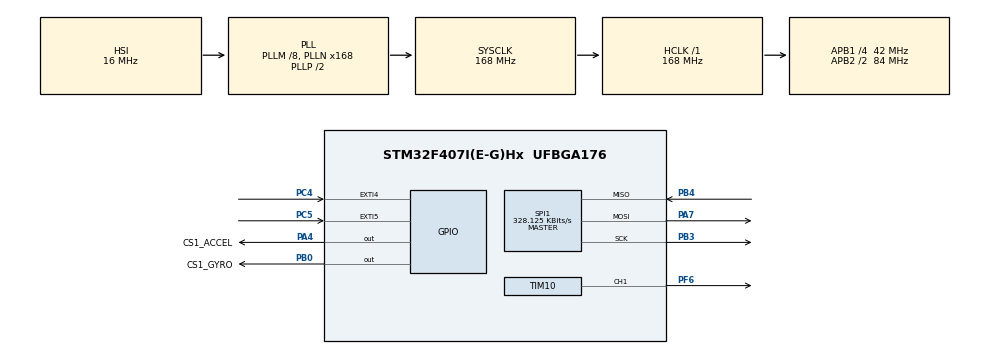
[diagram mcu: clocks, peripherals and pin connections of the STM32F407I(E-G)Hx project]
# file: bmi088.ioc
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Dma.Request0=SPI1_RX
Dma.Request1=SPI1_TX
Dma.SPI1_RX.0.Direction=DMA_PERIPH_TO_MEMORY
Dma.SPI1_RX.0.FIFOMode=DMA_FIFOMODE_DISABLE
Dma.SPI1_RX.0.Instance=DMA2_Stream2
Dma.SPI1_RX.0.MemDataAlignment=DMA_MDATAALIGN_BYTE
Dma.SPI1_RX.0.MemInc=DMA_MINC_ENABLE
Dma.SPI1_RX.0.Mode=DMA_NORMAL
Dma.SPI1_RX.0.PeriphDataAlignment=DMA_PDATAALIGN_BYTE
Dma.SPI1_RX.0.PeriphInc=DMA_PINC_DISABLE
Dma.SPI1_RX.0.Priority=DMA_PRIORITY_VERY_HIGH
Dma.SPI1_TX.1.Direction=DMA_MEMORY_TO_PERIPH
Dma.SPI1_TX.1.FIFOMode=DMA_FIFOMODE_DISABLE
Dma.SPI1_TX.1.Instance=DMA2_Stream3
Dma.SPI1_TX.1.MemDataAlignment=DMA_MDATAALIGN_BYTE
Dma.SPI1_TX.1.MemInc=DMA_MINC_ENABLE
Dma.SPI1_TX.1.Mode=DMA_NORMAL
Dma.SPI1_TX.1.PeriphDataAlignment=DMA_PDATAALIGN_BYTE
Dma.SPI1_TX.1.PeriphInc=DMA_PINC_DISABLE
Dma.SPI1_TX.1.Priority=DMA_PRIORITY_HIGH
Mcu.Family=STM32F4
Mcu.Name=STM32F407I(E-G)Hx
Mcu.Package=UFBGA176
NVIC.DMA2_Stream2_IRQn=true\:0\:0\:false\:false\:true\:false\:true\:true
NVIC.DMA2_Stream3_IRQn=true\:0\:0\:false\:false\:true\:false\:true\:true
NVIC.EXTI4_IRQn=true\:0\:0\:false\:false\:true\:true\:true\:true
NVIC.EXTI9_5_IRQn=true\:0\:0\:false\:false\:true\:true\:true\:true
NVIC.PriorityGroup=NVIC_PRIORITYGROUP_4
NVIC.TIM1_UP_TIM10_IRQn=true\:0\:0\:false\:false\:true\:true\:true\:true
PA13.Mode=Serial_Wire
PA13.Signal=SYS_JTMS-SWDIO
PA14.Mode=Serial_Wire
PA14.Signal=SYS_JTCK-SWCLK
PA4.GPIO_Label=CS1_ACCEL
PA4.GPIO_PuPd=GPIO_PULLUP
PA4.GPIO_Speed=GPIO_SPEED_FREQ_HIGH
PA4.PinState=GPIO_PIN_SET
PA4.Signal=GPIO_Output
PA7.Mode=Full_Duplex_Master
PA7.Signal=SPI1_MOSI
PB0.GPIO_Label=CS1_GYRO
PB0.GPIO_PuPd=GPIO_PULLUP
PB0.GPIO_Speed=GPIO_SPEED_FREQ_HIGH
PB0.PinState=GPIO_PIN_SET
PB0.Signal=GPIO_Output
PB3.Mode=Full_Duplex_Master
PB3.Signal=SPI1_SCK
PB4.Mode=Full_Duplex_Master
PB4.Signal=SPI1_MISO
PC14-OSC32_IN.Mode=LSE-External-Oscillator
PC14-OSC32_IN.Signal=RCC_OSC32_IN
PC15-OSC32_OUT.Mode=LSE-External-Oscillator
PC15-OSC32_OUT.Signal=RCC_OSC32_OUT
PC4.Signal=GPXTI4
PC5.Signal=GPXTI5
PF6.GPIO_PuPd=GPIO_PULLUP
PF6.GPIO_Speed=GPIO_SPEED_FREQ_HIGH
PF6.Signal=S_TIM10_CH1
PH0-OSC_IN.Mode=HSE-External-Oscillator
PH0-OSC_IN.Signal=RCC_OSC_IN
PH1-OSC_OUT.Mode=HSE-External-Oscillator
PH1-OSC_OUT.Signal=RCC_OSC_OUT
ProjectManager.HeapSize=0x200
ProjectManager.StackSize=0x400
ProjectManager.TargetToolchain=MDK-ARM V5.32
RCC.48MHZClocksFreq_Value=84000000
RCC.AHBFreq_Value=168000000
RCC.APB1CLKDivider=RCC_HCLK_DIV4
RCC.APB1Freq_Value=42000000
RCC.APB1TimFreq_Value=84000000
RCC.APB2CLKDivider=RCC_HCLK_DIV2
RCC.APB2Freq_Value=84000000
RCC.APB2TimFreq_Value=168000000
RCC.CortexFreq_Value=168000000
RCC.HCLKFreq_Value=168000000
RCC.HSE_VALUE=25000000
RCC.HSI_VALUE=16000000
RCC.PLLM=8
RCC.PLLN=168
RCC.SYSCLKFreq_VALUE=168000000
RCC.SYSCLKSource=RCC_SYSCLKSOURCE_PLLCLK
RCC.VCOOutputFreq_Value=336000000
SH.S_TIM10_CH1.0=TIM10_CH1,PWM Generation1 CH1
SPI1.BaudRatePrescaler=SPI_BAUDRATEPRESCALER_256
SPI1.CLKPhase=SPI_PHASE_2EDGE
SPI1.CLKPolarity=SPI_POLARITY_HIGH
SPI1.CalculateBaudRate=328.125 KBits/s
SPI1.Direction=SPI_DIRECTION_2LINES
SPI1.Mode=SPI_MODE_MASTER
SPI1.VirtualType=VM_MASTER
TIM10.Channel=TIM_CHANNEL_1
TIM10.Period=4999
VP_TIM10_VS_ClockSourceINT.Mode=Enable_Timer
board=custom

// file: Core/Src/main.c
/* USER CODE BEGIN Header */
/**
  ******************************************************************************
  * @file           : main.c
  * @brief          : Main program body
  ******************************************************************************
  * @attention
  *
  * Copyright (c) 2025 STMicroelectronics.
  * All rights reserved.
  *
  * This software is licensed under terms that can be found in the LICENSE file
  * in the root directory of this software component.
  * If no LICENSE file comes with this software, it is provided AS-IS.
  *
  ******************************************************************************
  */
/* USER CODE END Header */
#include "main.h"
#include "dma.h"
#include "spi.h"
#include "tim.h"
#include "gpio.h"

/* USER CODE BEGIN Includes */
#include "bmi088_driver.h"

/* USER CODE END Includes */

/* USER CODE BEGIN PV */
static fp32 gyro[3], accel[3], temp;

/* USER CODE END PV */

void SystemClock_Config(void);

int main(void)
{

  /* MCU Configuration--------------------------------------------------------*/

  /* Reset of all peripherals, Initializes the Flash interface and the Systick. */
  HAL_Init();

  /* Configure the system clock */
  SystemClock_Config();

  /* Initialize all configured peripherals */
  MX_GPIO_Init();
  MX_DMA_Init();
  MX_SPI1_Init();
  MX_TIM10_Init();
  /* USER CODE BEGIN 2 */
  while(BMI088_init())
     {
         ;
     }
  /* USER CODE END 2 */

  /* Infinite loop */
  while (1)
  {

    /* USER CODE BEGIN 3 */
     BMI088_read(gyro, accel, &temp);
     HAL_Delay(10);
  }
  /* USER CODE END 3 */
}

void SystemClock_Config(void)
{
  RCC_OscInitTypeDef RCC_OscInitStruct = {0};
  RCC_ClkInitTypeDef RCC_ClkInitStruct = {0};

  /** Configure the main internal regulator output voltage
  */
  __HAL_RCC_PWR_CLK_ENABLE();
  __HAL_PWR_VOLTAGESCALING_CONFIG(PWR_REGULATOR_VOLTAGE_SCALE1);

  /** Initializes the RCC Oscillators according to the specified parameters
  * in the RCC_OscInitTypeDef structure.
  */
  RCC_OscInitStruct.OscillatorType = RCC_OSCILLATORTYPE_HSI;
  RCC_OscInitStruct.HSIState = RCC_HSI_ON;
  RCC_OscInitStruct.HSICalibrationValue = RCC_HSICALIBRATION_DEFAULT;
  RCC_OscInitStruct.PLL.PLLState = RCC_PLL_ON;
  RCC_OscInitStruct.PLL.PLLSource = RCC_PLLSOURCE_HSI;
  RCC_OscInitStruct.PLL.PLLM = 8;
  RCC_OscInitStruct.PLL.PLLN = 168;
  RCC_OscInitStruct.PLL.PLLP = RCC_PLLP_DIV2;
  RCC_OscInitStruct.PLL.PLLQ = 4;
  if (HAL_RCC_OscConfig(&RCC_OscInitStruct) != HAL_OK)
  {
    Error_Handler();
  }

  /** Initializes the CPU, AHB and APB buses clocks
  */
  RCC_ClkInitStruct.ClockType = RCC_CLOCKTYPE_HCLK|RCC_CLOCKTYPE_SYSCLK
                              |RCC_CLOCKTYPE_PCLK1|RCC_CLOCKTYPE_PCLK2;
  RCC_ClkInitStruct.SYSCLKSource = RCC_SYSCLKSOURCE_PLLCLK;
  RCC_ClkInitStruct.AHBCLKDivider = RCC_SYSCLK_DIV1;
  RCC_ClkInitStruct.APB1CLKDivider = RCC_HCLK_DIV4;
  RCC_ClkInitStruct.APB2CLKDivider = RCC_HCLK_DIV2;

  if (HAL_RCC_ClockConfig(&RCC_ClkInitStruct, FLASH_LATENCY_5) != HAL_OK)
  {
    Error_Handler();
  }
}

void Error_Handler(void)
{
  __disable_irq();
  while (1)
  {
  }
}
